# SCB_356.0 register map
Vendor: Texas Instruments
Peripheral module from a debugger description file (folder MSP432).
Registers are 32-bit, read-only, no defined reset value unless marked. A register's access mark holds for its fields unless they carry their own. Offsets are as the file gives them; lines under a group give offsets from that group; [hi:lo] are bit positions; {n}, {i} and the like mark numbered series; 'fields as' and 'values as' point back to an identical list; <NAME> marks a mode.

## SCB
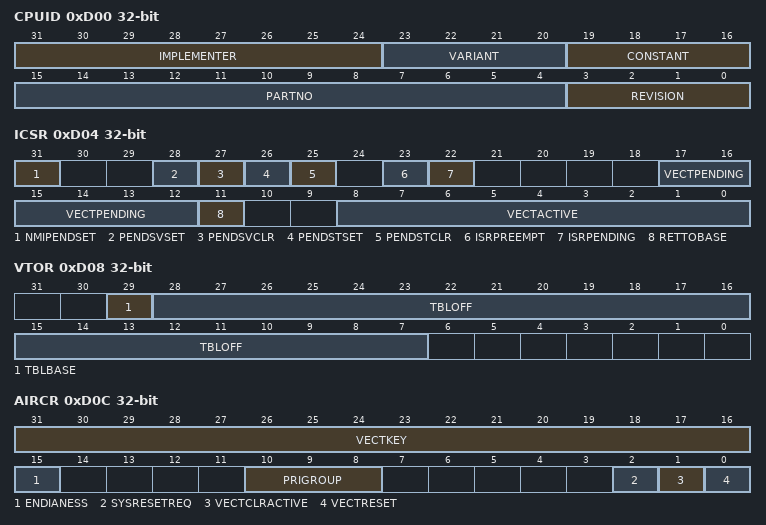
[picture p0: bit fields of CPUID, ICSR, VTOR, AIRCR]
0xD00 CPUID — CPUID Base Register
  [31:24] IMPLEMENTER — Implementor code.
  [23:20] VARIANT — Implementation defined variant number.
  [19:16] CONSTANT — Reads as 0xC
  [15:4] PARTNO — Number of processor within family.
  [3:0] REVISION — Implementation defined revision number.
0xD04 ICSR access per field — Interrupt Control State Register
  [31] NMIPENDSET rw — Set pending NMI bit. NMIPENDSET pends and activates an NMI. Because NMI is the highest-priority interrupt, it takes effect as soon as it registers.
    0=en_0b0 (do not set pending NMI); 1=en_0b1 (set pending NMI)
  [28] PENDSVSET rw — Set pending pendSV bit.
    0=en_0b0 (do not set pending pendSV); 1=en_0b1 (set pending PendSV)
  [27] PENDSVCLR rw — Clear pending pendSV bit
    0=en_0b0 (do not clear pending pendSV); 1=en_0b1 (clear pending pendSV)
  [26] PENDSTSET rw — Set a pending SysTick bit.
    0=en_0b0 (do not set pending SysTick); 1=en_0b1 (set pending SysTick)
  [25] PENDSTCLR rw — Clear pending SysTick bit
    0=en_0b0 (do not clear pending SysTick); 1=en_0b1 (clear pending SysTick)
  [23] ISRPREEMPT ro — You must only use this at debug time. It indicates that a pending interrupt is to be taken in the next running cycle. If C_MASKINTS is clear in the Debug Halting Control and Status Register, the interrupt is serviced.
    0=en_0b0 (a pending exception is not serviced.); 1=en_0b1 (a pending exception is serviced on exit from the debug halt state)
  [22] ISRPENDING ro — Interrupt pending flag. Excludes NMI and faults.
    0=en_0b0 (interrupt not pending); 1=en_0b1 (interrupt pending)
  [17:12] VECTPENDING ro — Pending ISR number field. VECTPENDING contains the interrupt number of the highest priority pending ISR.
  [11] RETTOBASE ro — This bit is 1 when the set of all active exceptions minus the IPSR_current_exception yields the empty set.
  [8:0] VECTACTIVE ro — Active ISR number field. Reset clears the VECTACTIVE field.
0xD08 VTOR rw — Vector Table Offset Register
  [29] TBLBASE — Table base is in Code (0) or RAM (1).
  [28:7] TBLOFF — Vector table base offset field. Contains the offset of the table base from the bottom of the SRAM or CODE space.
0xD0C AIRCR access per field — Application Interrupt/Reset Control Register
  [31:16] VECTKEY rw — Register key. Writing to this register requires 0x5FA in the VECTKEY field. Otherwise the write value is ignored.
  [15] ENDIANESS ro — Data endianness bit. ENDIANNESS is sampled from the BIGEND input port during reset. You cannot change ENDIANNESS outside of reset.
    0=en_0b0 (little endian); 1=en_0b1 (big endian)
  [10:8] PRIGROUP rw — Interrupt priority grouping field. The PRIGROUP field is a binary point position indicator for creating subpriorities for exceptions that share the same pre-emption level. It divides the PRI_n field in the Interrupt Priority Register into a pre-emption level and a subpriority level. The binary point is a left-of value. This means that the PRIGROUP value represents a point starting at the left of the Least Significant Bit (LSB). This is bit [0] of 7:0. The lowest value might not be 0 depending on the number of bits allocated for priorities, and implementation choices
  [2] SYSRESETREQ rw — Causes a signal to be asserted to the outer system that indicates a reset is requested. Intended to force a large system reset of all major components except for debug. Setting this bit does not prevent Halting Debug from running.
  [1] VECTCLRACTIVE rw — Clears all active state information for active NMI, fault, and interrupts. It is the responsibility of the application to reinitialize the stack. The VECTCLRACTIVE bit is for returning to a known state during debug. The VECTCLRACTIVE bit self-clears. IPSR is not cleared by this operation. So, if used by an application, it must only be used at the base level of activation, or within a system handler whose active bit can be set.
  [0] VECTRESET rw — System Reset bit. Resets the system, with the exception of debug components. The VECTRESET bit self-clears. Reset clears the VECTRESET bit. For debugging, only write this bit when the core is halted.
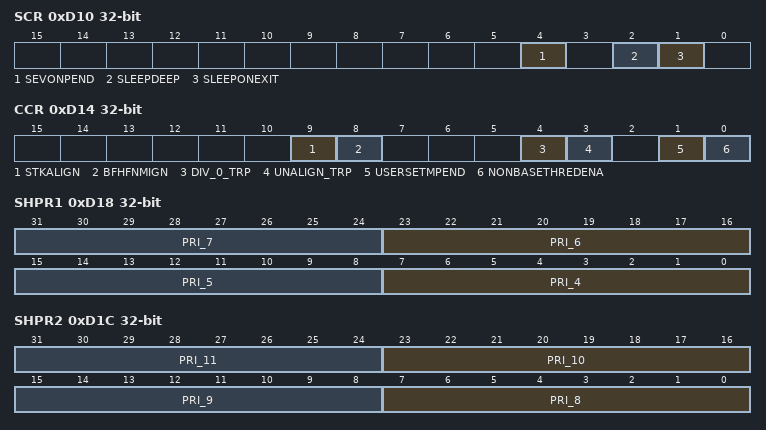
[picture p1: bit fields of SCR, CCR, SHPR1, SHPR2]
0xD10 SCR rw — System Control Register
  [4] SEVONPEND — When enabled, this causes WFE to wake up when an interrupt moves from inactive to pended. Otherwise, WFE only wakes up from an event signal, external and SEV instruction generated. The event input, RXEV, is registered even when not waiting for an event, and so effects the next WFE.
  [2] SLEEPDEEP — Sleep deep bit.
    0=en_0b0 (not OK to turn off system clock); 1=en_0b1 (indicates to the system that Cortex-M4 clock can be stopped. Setting this bit causes the SLEEPDEEP port to be asserted when the processor can be stopped.)
  [1] SLEEPONEXIT — Sleep on exit when returning from Handler mode to Thread mode. Enables interrupt driven applications to avoid returning to empty main application.
    0=en_0b0 (do not sleep when returning to thread mode); 1=en_0b1 (sleep on ISR exit)
0xD14 CCR rw — Configuration Control Register
  [9] STKALIGN — Stack alignment bit.
    0=en_0b0 (Only 4-byte alignment is guaranteed for the SP used prior to the exception on exception entry.); 1=en_0b1 (On exception entry, the SP used prior to the exception is adjusted to be 8-byte aligned and the context to restore it is saved. The SP is restored on the associated exception return.)
  [8] BFHFNMIGN — When enabled, this causes handlers running at priority -1 and -2 (Hard Fault, NMI, and FAULTMASK escalated handlers) to ignore Data Bus faults caused by load and store instructions. When disabled, these bus faults cause a lock-up. You must only use this enable with extreme caution. All data bus faults are ignored therefore you must only use it when the handler and its data are in absolutely safe memory. Its normal use is to probe system devices and bridges to detect control path problems and fix them.
  [4] DIV_0_TRP — Trap on Divide by 0. This enables faulting/halting when an attempt is made to divide by 0. The relevant Usage Fault Status Register bit is DIVBYZERO.
  [3] UNALIGN_TRP — Trap for unaligned access. This enables faulting/halting on any unaligned half or full word access. Unaligned load-store multiples always fault. The relevant Usage Fault Status Register bit is UNALIGNED.
  [1] USERSETMPEND — If written as 1, enables user code to write the Software Trigger Interrupt register to trigger (pend) a Main exception, which is one associated with the Main stack pointer.
  [0] NONBASETHREDENA — When 0, default, It is only possible to enter Thread mode when returning from the last exception. When set to 1, Thread mode can be entered from any level in Handler mode by controlled return value.
0xD18 SHPR1 rw — System Handlers 4-7 Priority Register
  [8n-25:8n-32] PRI_{n} (n=4..7) — Priority of system handler {n}.
0xD1C SHPR2 rw — System Handlers 8-11 Priority Register
  [8n-57:8n-64] PRI_{n} (n=8..11) — Priority of system handler {n}.
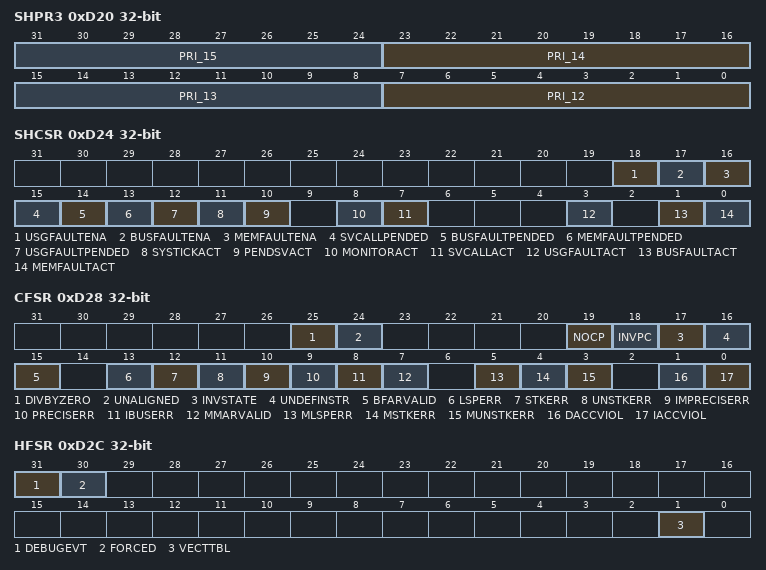
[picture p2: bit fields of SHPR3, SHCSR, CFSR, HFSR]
0xD20 SHPR3 rw — System Handlers 12-15 Priority Register
  [8n-89:8n-96] PRI_{n} (n=12..15) — Priority of system handler {n}.
0xD24 SHCSR access per field — System Handler Control and State Register
  [18] USGFAULTENA rw — Usage fault system handler enable
    0=en_0b0 (disabled); 1=en_0b1 (enabled)
  [17] BUSFAULTENA rw — Bus fault system handler enable
    0=en_0b0 (disabled); 1=en_0b1 (enabled)
  [16] MEMFAULTENA rw — MemManage fault system handler enable
    0=en_0b0 (disabled); 1=en_0b1 (enabled)
  [15] SVCALLPENDED ro — SVCall pended flag.
    0=en_0b0 (not pended); 1=en_0b1 (pended)
  [14] BUSFAULTPENDED ro — BusFault pended flag.
    0=en_0b0 (not pended); 1=en_0b1 (pended)
  [13] MEMFAULTPENDED ro — MemManage pended flag.
    0=en_0b0 (not pended); 1=en_0b1 (pended)
  [12] USGFAULTPENDED ro — usage fault pended flag.
    0=en_0b0 (not pended); 1=en_0b1 (pended)
  [11] SYSTICKACT ro — SysTick active flag.
    0=en_0b0 (not active); 1=en_0b1 (active)
  [10] PENDSVACT ro — PendSV active flag.
    0=en_0b0 (not active); 1=en_0b1 (active)
  [8] MONITORACT ro — the Monitor active flag.
    0=en_0b0 (not active); 1=en_0b1 (active)
  [7] SVCALLACT ro — SVCall active flag.
    0=en_0b0 (not active); 1=en_0b1 (active)
  [3] USGFAULTACT ro — UsageFault active flag.
    0=en_0b0 (not active); 1=en_0b1 (active)
  [1] BUSFAULTACT ro — BusFault active flag.
    0=en_0b0 (not active); 1=en_0b1 (active)
  [0] MEMFAULTACT ro — MemManage active flag.
    0=en_0b0 (not active); 1=en_0b1 (active)
0xD28 CFSR rw — Configurable Fault Status Registers
  [25] DIVBYZERO — When DIV_0_TRP (see Configuration Control Register on page 8-26) is enabled and an SDIV or UDIV instruction is used with a divisor of 0, this fault occurs The instruction is executed and the return PC points to it. If DIV_0_TRP is not set, then the divide returns a quotient of 0.
  [24] UNALIGNED — When UNALIGN_TRP is enabled (see Configuration Control Register on page 8-26), and there is an attempt to make an unaligned memory access, then this fault occurs. Unaligned LDM/STM/LDRD/STRD instructions always fault irrespective of the setting of UNALIGN_TRP.
  [19] NOCP — Attempt to use a coprocessor instruction. The processor does not support coprocessor instructions.
  [18] INVPC — Attempt to load EXC_RETURN into PC illegally. Invalid instruction, invalid context, invalid value. The return PC points to the instruction that tried to set the PC.
  [17] INVSTATE — Invalid combination of EPSR and instruction, for reasons other than UNDEFINED instruction. Return PC points to faulting instruction, with the invalid state.
  [16] UNDEFINSTR — The UNDEFINSTR flag is set when the processor attempts to execute an undefined instruction. This is an instruction that the processor cannot decode. The return PC points to the undefined instruction.
  [15] BFARVALID — This bit is set if the Bus Fault Address Register (BFAR) contains a valid address. This is true after a bus fault where the address is known. Other faults can clear this bit, such as a Mem Manage fault occurring later. If a Bus fault occurs that is escalated to a Hard Fault because of priority, the Hard Fault handler must clear this bit. This prevents problems if returning to a stacked active Bus fault handler whose BFAR value has been overwritten.
  [13] LSPERR — Indicates if bus fault occurred during FP lazy state preservation.
  [12] STKERR — Stacking from exception has caused one or more bus faults. The SP is still adjusted and the values in the context area on the stack might be incorrect. The BFAR is not written.
  [11] UNSTKERR — Unstack from exception return has caused one or more bus faults. This is chained to the handler, so that the original return stack is still present. SP is not adjusted from failing return and new save is not performed. The BFAR is not written.
  [10] IMPRECISERR — Imprecise data bus error. It is a BusFault, but the Return PC is not related to the causing instruction. This is not a synchronous fault. So, if detected when the priority of the current activation is higher than the Bus Fault, it only pends. Bus fault activates when returning to a lower priority activation. If a precise fault occurs before returning to a lower priority exception, the handler detects both IMPRECISERR set and one of the precise fault status bits set at the same time. The BFAR is not written.
  [9] PRECISERR — Precise data bus error return.
  [8] IBUSERR — Instruction bus error flag. The IBUSERR flag is set by a prefetch error. The fault stops on the instruction, so if the error occurs under a branch shadow, no fault occurs. The BFAR is not written.
  [7] MMARVALID — Memory Manage Address Register (MMAR) address valid flag. A later-arriving fault, such as a bus fault, can clear a memory manage fault.. If a MemManage fault occurs that is escalated to a Hard Fault because of priority, the Hard Fault handler must clear this bit. This prevents problems on return to a stacked active MemManage handler whose MMAR value has been overwritten.
  [5] MLSPERR — Indicates if MemManage fault occurred during FP lazy state preservation.
  [4] MSTKERR — Stacking from exception has caused one or more access violations. The SP is still adjusted and the values in the context area on the stack might be incorrect. The MMAR is not written.
  [3] MUNSTKERR — Unstack from exception return has caused one or more access violations. This is chained to the handler, so that the original return stack is still present. SP is not adjusted from failing return and new save is not performed. The MMAR is not written.
  [1] DACCVIOL — Data access violation flag. Attempting to load or store at a location that does not permit the operation sets the DACCVIOL flag. The return PC points to the faulting instruction. This error loads MMAR with the address of the attempted access.
  [0] IACCVIOL — Instruction access violation flag. Attempting to fetch an instruction from a location that does not permit execution sets the IACCVIOL flag. This occurs on any access to an XN region, even when the MPU is disabled or not present. The return PC points to the faulting instruction. The MMAR is not written.
0xD2C HFSR rw — Hard Fault Status Register
  [31] DEBUGEVT — This bit is set if there is a fault related to debug. This is only possible when halting debug is not enabled. For monitor enabled debug, it only happens for BKPT when the current priority is higher than the monitor. When both halting and monitor debug are disabled, it only happens for debug events that are not ignored (minimally, BKPT). The Debug Fault Status Register is updated.
  [30] FORCED — Hard Fault activated because a Configurable Fault was received and cannot activate because of priority or because the Configurable Fault is disabled. The Hard Fault handler then has to read the other fault status registers to determine cause.
  [1] VECTTBL — This bit is set if there is a fault because of vector table read on exception processing (Bus Fault). This case is always a Hard Fault. The return PC points to the pre-empted instruction.
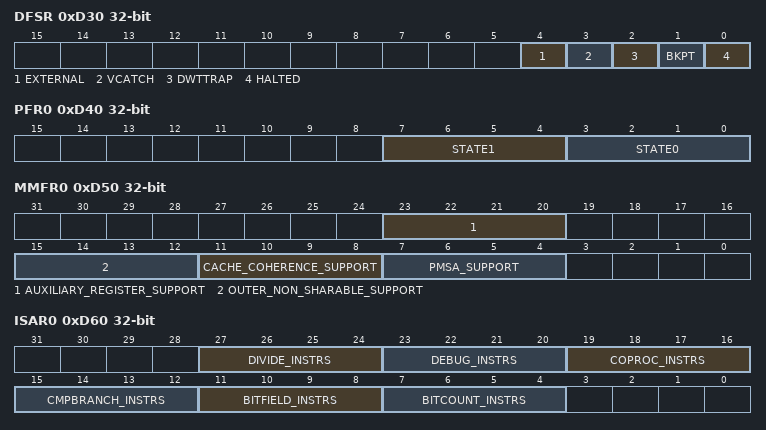
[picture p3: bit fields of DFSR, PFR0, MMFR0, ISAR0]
0xD30 DFSR rw — Debug Fault Status Register
  [4] EXTERNAL — External debug request flag. The processor stops on next instruction boundary.
    0=en_0b0 (EDBGRQ signal not asserted); 1=en_0b1 (EDBGRQ signal asserted)
  [3] VCATCH — Vector catch flag. When the VCATCH flag is set, a flag in one of the local fault status registers is also set to indicate the type of fault.
    0=en_0b0 (no vector catch occurred); 1=en_0b1 (vector catch occurred)
  [2] DWTTRAP — Data Watchpoint and Trace (DWT) flag. The processor stops at the current instruction or at the next instruction.
    0=en_0b0 (no DWT match); 1=en_0b1 (DWT match)
  [1] BKPT — BKPT flag. The BKPT flag is set by a BKPT instruction in flash patch code, and also by normal code. Return PC points to breakpoint containing instruction.
    0=en_0b0 (no BKPT instruction execution); 1=en_0b1 (BKPT instruction execution)
  [0] HALTED — Halt request flag. The processor is halted on the next instruction.
    0=en_0b0 (no halt request); 1=en_0b1 (halt requested by NVIC, including step)
0xD34 MMFAR access not given — Mem Manage Fault Address Register
0xD38 BFAR access not given — Bus Fault Address Register
0xD3C AFSR access not given — Auxiliary Fault Status Register
0xD40 PFR0 — Processor Feature register0
  [7:4] STATE1 — State1 (T-bit == 1)
    0=en_0b0000 (N/A); 1=en_0b0001 (N/A); 2=en_0b0010 (Thumb-2 encoding with the 16-bit basic instructions plus 32-bit Buncond/BL but no other 32-bit basic instructions (Note non-basic 32-bit instructions can be added using the appropriate instruction attribute, but other 32-bit basic instructions cannot.)); 3=en_0b0011 (Thumb-2 encoding with all Thumb-2 basic instructions)
  [3:0] STATE0 — State0 (T-bit == 0)
    0=en_0b0000 (no ARM encoding); 1=en_0b0001 (N/A)
0xD44 PFR1 — Processor Feature register1
  [11:8] MICROCONTROLLER_PROGRAMMERS_MODEL
    0=en_0b0000 (not supported); 2=en_0b0010 (two-stack support)
0xD48 DFR0 — Debug Feature register0
  [23:20] MICROCONTROLLER_DEBUG_MODEL — Microcontroller Debug Model - memory mapped
    0=en_0b0000 (not supported); 1=en_0b0001 (Microcontroller debug v1 (ITMv1, DWTv1, optional ETM))
0xD4C AFR0 access not given — Auxiliary Feature register0
0xD50 MMFR0 — Memory Model Feature register0
  [23:20] AUXILIARY_REGISTER_SUPPORT
    0=en_0b0000 (not supported); 1=en_0b0001 (Auxiliary control register)
  [15:12] OUTER_NON_SHARABLE_SUPPORT
    0=en_0b0000 (Outer non-sharable not supported); 1=en_0b0001 (Outer sharable supported)
  [11:8] CACHE_COHERENCE_SUPPORT
    0=en_0b0000 (no shared support); 1=en_0b0001 (partial-inner-shared coherency (coherency amongst some - but not all - of the entities within an inner-coherent domain)); 2=en_0b0010 (full-inner-shared coherency (coherency amongst all of the entities within an inner-coherent domain)); 3=en_0b0011 (full coherency (coherency amongst all of the entities))
  [7:4] PMSA_SUPPORT
    0=en_0b0000 (not supported); 1=en_0b0001 (IMPLEMENTATION DEFINED (N/A)); 2=en_0b0010 (PMSA base (features as defined for ARMv6) (N/A)); 3=en_0b0011 (PMSAv7 (base plus subregion support))
0xD54 MMFR1 access not given — Memory Model Feature register1
0xD58 MMFR2 — Memory Model Feature register2
  [27:24] WAIT_FOR_INTERRUPT_STALLING
    0=en_0b0000 (not supported); 1=en_0b0001 (wait for interrupt supported)
0xD5C MMFR3 access not given — Memory Model Feature register3
0xD60 ISAR0 — ISA Feature register0
  [27:24] DIVIDE_INSTRS — Divide instructions
    0=en_0b0000 (no divide instructions present); 1=en_0b0001 (adds SDIV, UDIV (v1 quotient only result))
  [23:20] DEBUG_INSTRS — Debug instructions
    0=en_0b0000 (no debug instructions present); 1=en_0b0001 (adds BKPT)
  [19:16] COPROC_INSTRS — Coprocessor instructions
    0=en_0b0000 (no coprocessor support, other than for separately attributed architectures such as CP15 or VFP); 1=en_0b0001 (adds generic CDP, LDC, MCR, MRC, STC); 2=en_0b0010 (adds generic CDP2, LDC2, MCR2, MRC2, STC2); 3=en_0b0011 (adds generic MCRR, MRRC); 4=en_0b0100 (adds generic MCRR2, MRRC2)
  [15:12] CMPBRANCH_INSTRS — CmpBranch instructions
    0=en_0b0000 (no combined compare-and-branch instructions present); 1=en_0b0001 (adds CB{N}Z)
  [11:8] BITFIELD_INSTRS — BitField instructions
    0=en_0b0000 (no bitfield instructions present); 1=en_0b0001 (adds BFC, BFI, SBFX, UBFX)
  [7:4] BITCOUNT_INSTRS — BitCount instructions
    0=en_0b0000 (no bit-counting instructions present); 1=en_0b0001 (adds CLZ)
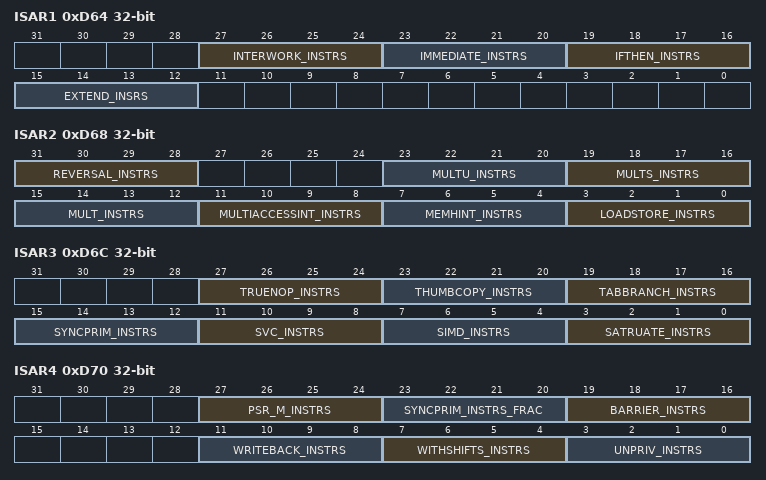
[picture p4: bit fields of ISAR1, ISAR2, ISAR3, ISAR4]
0xD64 ISAR1 — ISA Feature register1
  [27:24] INTERWORK_INSTRS — Interwork instructions
    0=en_0b0000 (no interworking instructions supported); 1=en_0b0001 (adds BX (and T bit in PSRs)); 2=en_0b0010 (adds BLX, and PC loads have BX-like behavior); 3=en_0b0011 (N/A)
  [23:20] IMMEDIATE_INSTRS — Immediate instructions
    0=en_0b0000 (no special immediate-generating instructions present); 1=en_0b0001 (adds ADDW, MOVW, MOVT, SUBW)
  [19:16] IFTHEN_INSTRS — IfThen instructions
    0=en_0b0000 (IT instructions not present); 1=en_0b0001 (adds IT instructions (and IT bits in PSRs))
  [15:12] EXTEND_INSRS — Extend instructions. Note that the shift options on these instructions are also controlled by the WithShifts_instrs attribute.
    0=en_0b0000 (no scalar (i.e. non-SIMD) sign/zero-extend instructions present); 1=en_0b0001 (adds SXTB, SXTH, UXTB, UXTH); 2=en_0b0010 (N/A)
0xD68 ISAR2 — ISA Feature register2
  [31:28] REVERSAL_INSTRS — Reversal instructions
    0=en_0b0000 (no reversal instructions present); 1=en_0b0001 (adds REV, REV16, REVSH); 2=en_0b0010 (adds RBIT)
  [23:20] MULTU_INSTRS — Multiply instructions (advanced, unsigned)
    0=en_0b0000 (no unsigned multiply instructions present); 1=en_0b0001 (adds UMULL, UMLAL); 2=en_0b0010 (N/A)
  [19:16] MULTS_INSTRS — Multiply instructions (advanced, signed)
    0=en_0b0000 (no signed multiply instructions present); 1=en_0b0001 (adds SMULL, SMLAL); 2=en_0b0010 (N/A); 3=en_0b0011 (N/A)
  [15:12] MULT_INSTRS — Multiply instructions
    0=en_0b0000 (only MUL present); 1=en_0b0001 (adds MLA); 2=en_0b0010 (adds MLS)
  [11:8] MULTIACCESSINT_INSTRS — Multi-Access interruptible instructions
    0=en_0b0000 (the (LDM/STM) instructions are non-interruptible); 1=en_0b0001 (the (LDM/STM) instructions are restartable); 2=en_0b0010 (the (LDM/STM) instructions are continuable)
  [7:4] MEMHINT_INSTRS — MemoryHint instructions
    0=en_0b0000 (no memory hint instructions presen); 1=en_0b0001 (adds PLD); 2=en_0b0010 (adds PLD (ie a repeat on value 1)); 3=en_0b0011 (adds PLI)
  [3:0] LOADSTORE_INSTRS — LoadStore instructions
    0=en_0b0000 (no additional normal load/store instructions present); 1=en_0b0001 (adds LDRD/STRD)
0xD6C ISAR3 — ISA Feature register3
  [27:24] TRUENOP_INSTRS — TrueNOP instructions
    0=en_0b0000 (true NOP instructions not present - that is, NOP instructions with no register dependencies); 1=en_0b0001 (adds "true NOP", and the capability of additional "NOP compatible hints")
  [23:20] THUMBCOPY_INSTRS — ThumbCopy instructions
    0=en_0b0000 (Thumb MOV(register) instruction does not allow low reg - low reg); 1=en_0b0001 (adds Thumb MOV(register) low reg - low reg and the CPY alias)
  [19:16] TABBRANCH_INSTRS — TableBranch instructions
    0=en_0b0000 (no table-branch instructions present); 1=en_0b0001 (adds TBB, TBH)
  [15:12] SYNCPRIM_INSTRS — SyncPrim instructions. Note there are no LDREXD or STREXD in ARMv7-M. This attribute is used in conjunction with the SyncPrim_instrs_frac attribute in ID_ISAR4[23:20].
    0=en_0b0000 (no synchronization primitives present); 1=en_0b0001 (adds LDREX, STREX); 2=en_0b0010 (adds LDREXB, LDREXH, LDREXD, STREXB, STREXH, STREXD, CLREX(N/A))
  [11:8] SVC_INSTRS — SVC instructions
    0=en_0b0000 (no SVC (SWI) instructions present); 1=en_0b0001 (adds SVC (SWI))
  [7:4] SIMD_INSTRS — SIMD instructions
    0=en_0b0000 (no SIMD instructions present); 1=en_0b0001 (adds SSAT, USAT (and the Q flag in the PSRs)); 3=en_0b0011 (N/A)
  [3:0] SATRUATE_INSTRS — Saturate instructions
    0=en_0b0000 (no non-SIMD saturate instructions present); 1=en_0b0001 (N/A)
0xD70 ISAR4 — ISA Feature register4
  [27:24] PSR_M_INSTRS
    0=en_0b0000 (instructions not present); 1=en_0b0001 (adds CPS, MRS, and MSR instructions (M-profile forms))
  [23:20] SYNCPRIM_INSTRS_FRAC
    0=en_0b0000 (no additional support); 3=en_0b0011 (adds CLREX, LDREXB, STREXB, LDREXH, STREXH)
  [19:16] BARRIER_INSTRS — Barrier instructions
    0=en_0b0000 (no barrier instructions supported); 1=en_0b0001 (adds DMB, DSB, ISB barrier instructions)
  [11:8] WRITEBACK_INSTRS — Writeback instructions
    0=en_0b0000 (only non-writeback addressing modes present, except that LDMIA/STMDB/PUSH/POP instructions support writeback addressing.); 1=en_0b0001 (adds all currently-defined writeback addressing modes (ARMv7, Thumb-2))
  [7:4] WITHSHIFTS_INSTRS — WithShift instructions. Note that all additions only apply in cases where the encoding supports them - e.g. there is no difference between levels 3 and 4 in the Thumb-2 instruction set. Also note that MOV instructions with shift options should instead be treated as ASR, LSL, LSR, ROR or RRX instructions.
    0=en_0b0000 (non-zero shifts only support MOV and shift instructions (see notes)); 1=en_0b0001 (shifts of loads/stores over the range LSL 0-3); 3=en_0b0010 (adds other constant shift options.); 4=en_0b0100 (adds register-controlled shift options.)
  [3:0] UNPRIV_INSTRS — Unprivileged instructions
    0=en_0b0000 (no "T variant" instructions exist); 1=en_0b0001 (adds LDRBT, LDRT, STRBT, STRT); 2=en_0b0010 (adds LDRHT, LDRSBT, LDRSHT, STRHT)
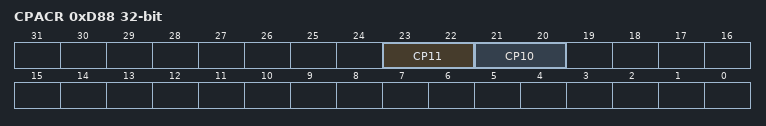
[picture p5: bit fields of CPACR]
0xD88 CPACR rw — Coprocessor Access Control Register
  [23:22] CP11 — Access privileges for coprocessor 11. The possible values of each field are: 0b00 = Access denied. Any attempted access generates a NOCP UsageFault. 0b01 = Privileged access only. An unprivileged access generates a NOCP UsageFault. 0b10 = Reserved. 0b11 = Full access. Used in conjunction with the control for CP10, this controls access to the Floating Point Coprocessor.
  [21:20] CP10 — Access privileges for coprocessor 10. The possible values of each field are: 0b00 = Access denied. Any attempted access generates a NOCP UsageFault. 0b01 = Privileged access only. An unprivileged access generates a NOCP UsageFault. 0b10 = Reserved. 0b11 = Full access. Used in conjunction with the control for CP11, this controls access to the Floating Point Coprocessor.
